# MPY_16__Multiplier__16_Bit_Mode_1 register map
Vendor: Texas Instruments
Peripheral module from a debugger description file (folder msp430).
Registers are 16-bit, access not given, no defined reset value unless marked. A register's access mark holds for its fields unless they carry their own. Offsets are as the file gives them; lines under a group give offsets from that group; [hi:lo] are bit positions; {n}, {i} and the like mark numbered series; 'fields as' and 'values as' point back to an identical list; <NAME> marks a mode.

## MPY_16_Multiplier_16_Bit_Mode
0x4C0 MPY — Multiply Unsigned/Operand 1
0x4C2 MPYS — Multiply Signed/Operand 1
0x4C4 MAC — Multiply Unsigned and Accumulate/Operand 1
0x4C6 MACS — Multiply Signed and Accumulate/Operand 1
0x4C8 OP2 — Operand 2
0x4CA RESLO — Result Low Word
0x4CC RESHI — Result High Word
0x4CE SUMEXT — Sum Extend
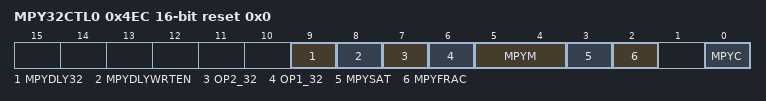
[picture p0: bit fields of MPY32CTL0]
0x4EC MPY32CTL0 rw reset 0x0 — MPY32 Control Register 0
  [9] MPYDLY32 — Delayed write mode
  [8] MPYDLYWRTEN — Delayed write enable
  [7] OP2_32 — Bit-width of operand 2 0:16Bit / 1:32Bit
  [6] OP1_32 — Bit-width of operand 1 0:16Bit / 1:32Bit
  [5:4] MPYM — Multiplier mode Bit:0
    0=Multiplier mode: MPY; 1=Multiplier mode: MPYS; 2=Multiplier mode: MAC; 3=Multiplier mode: MACS
  [3] MPYSAT — Saturation mode
  [2] MPYFRAC — Fractional mode
  [0] MPYC — Carry of the multiplier
